# CY8C4xxx register map
File version: 0.1
Registers are 8-bit, read-write, no defined reset value unless marked. A register's access mark holds for its fields unless they carry their own. Offsets are from the block's base; [hi:lo] are bit positions; {n}, {i} and the like mark numbered series; 'fields as' and 'values as' point back to an identical list.

## SCB0 (part 2 of 2) — Serial Communications Block (SPI/UART/I2C)
Base 0x40060000
Same registers: SCB1 0x40070000
0x104 BIST_DATA 32-bit
  [15:0] RAM_DATA — Data pattern for BIST sequence. If RAM_WORD=0, only bits [7:0] are used.
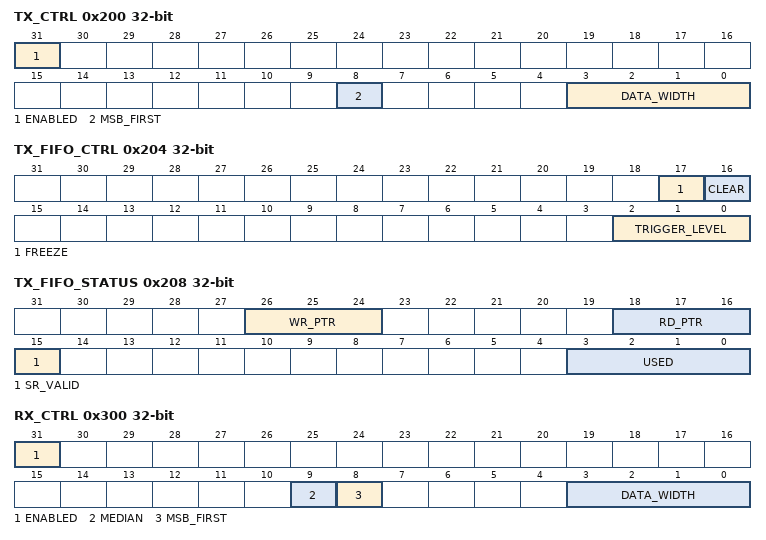
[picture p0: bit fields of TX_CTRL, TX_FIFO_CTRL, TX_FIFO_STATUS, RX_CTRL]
0x200 TX_CTRL 32-bit — Transmitter control register.
  [31] ENABLED — Transmitter enabled. The transmitter should be enabled for all protocols that transmit data (from either the EZ memory or from the TX FIFO). If not enabled, the protocol may not function as it does not get data to transmit.
  [8] MSB_FIRST — Least significant bit first ('0') or most significant bit first ('1'). For I2C, this field should be '1'.
  [3:0] DATA_WIDTH — Dataframe width. DATA_WIDTH + 1 is the amount of bits in a transmitted data frame. This number does not include start, parity and stop bits. For UART mode, the valid range is [3, 8]. For SPI, the valid range is [3, 15]. For I2C the only valid value is 7.
0x204 TX_FIFO_CTRL 32-bit — Transmitter FIFO control register.
  [17] FREEZE — When '1', hardware reads from the transmitter FIFO do not remove FIFO entries. Freeze will not advance the TX FIFO read pointer.
  [16] CLEAR — When '1', the transmitter FIFO and transmitter shift register are cleared/invalidated. Invalidation will last for as long as this field is '1'. If a quick clear/invalidation is required, the field should be set to '1' and be followed by a set to '0'. If a clear/invalidation is required for an extended time period, the field should be set to '1' during the complete time period.
  [2:0] TRIGGER_LEVEL — Trigger level. When the transmitter FIFO has less entries than the amount of this field, a transmitter trigger event is generated.
0x208 TX_FIFO_STATUS 32-bit — Transmitter FIFO status register.
  [26:24] WR_PTR ro — FIFO write pointer: FIFO location at which a new data frame is written.
  [18:16] RD_PTR ro — FIFO read pointer: FIFO location from which a data frame is read by the hardware.
  [15] SR_VALID ro — Indicates whether the TX shift registers holds a valid data frame ('1') or not ('0'). The shift register can be considered the top of the TX FIFO (the data frame is not included in the USED field of the TX FIFO). The shift register is a working register and holds the data frame that is currently transmitted (when the protocol state machine is transmitting a data frame) or the data frame that is tranmitted next (when the protocol state machine is not transmitting a data frame).
  [3:0] USED ro — Amount of enties in the transmitter FIFO. The value of this field ranges from 0 to 8.
0x240 TX_FIFO_WR 32-bit — Transmitter FIFO write register.
  [15:0] DATA wo — Data frame written into the transmitter FIFO. Behavior is similar to that of a PUSH operation.
0x300 RX_CTRL 32-bit — Receiver control register.
  [31] ENABLED — Receiver enabled. The receiver should be enabled for all protocols that receive data (to either the EZ memory or to the RX FIFO). If not enabled, the protocol may not function or received data may get lost.
  [9] MEDIAN — Median filter. When '1', a digital 3 taps median filter is performed on input interface lines. This filter should reduce the susceptability to errors. However, its requires higher oversampling values. For UART IrDA submode, this field should always be '1'.
  [8] MSB_FIRST — Least significant bit first ('0') or most significant bit first ('1'). For I2C, this field should be '1'.
  [3:0] DATA_WIDTH — Dataframe width. DATA_WIDTH + 1 is the expected amount of bits in received data frame. This number does not include start, parity and stop bits. For UART mode, the valid range is [3, 8]. For SPI, the valid range is [3, 15]. For I2C the only valid value is 7. In EZ mode (for both SPI and I2C), the only valid value is 7.
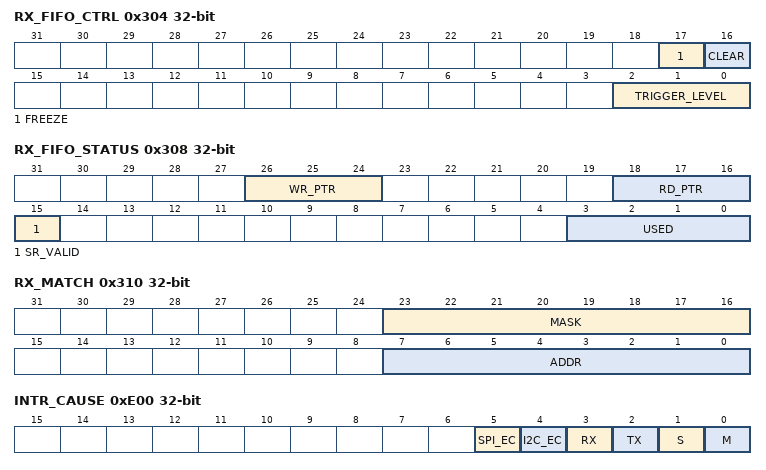
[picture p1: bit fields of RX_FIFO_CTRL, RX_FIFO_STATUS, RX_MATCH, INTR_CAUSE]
0x304 RX_FIFO_CTRL 32-bit — Receiver FIFO control register.
  [17] FREEZE — When '1', hardware writes to the receiver FIFO have no effect. Freeze will not advance the RX FIFO write pointer.
  [16] CLEAR — When '1', the receiver FIFO and receiver shift register are cleared/invalidated. Invalidation will last for as long as this field is '1'. If a quick clear/invalidation is required, the field should be set to '1' and be followed by a set to '0'. If a clear/invalidation is required for an extended time period, the field should be set to '1' during the complete time period.
  [2:0] TRIGGER_LEVEL — Trigger level. When the receiver FIFO has more entries than the amount of this field, a receiver trigger event is generated.
0x308 RX_FIFO_STATUS 32-bit — Receiver FIFO status register.
  [26:24] WR_PTR ro — FIFO write pointer: FIFO location at which a new data frame is written by the hardware.
  [18:16] RD_PTR ro — FIFO read pointer: FIFO location from which a data frame is read.
  [15] SR_VALID ro — Indicates whether the RX shift registers holds a (partial) valid data frame ('1') or not ('0'). The shift register can be considered the bottom of the RX FIFO (the data frame is not included in the USED field of the RX FIFO). The shift register is a working register and holds the data frame that is currently being received (when the protocol state machine is receiving a data frame).
  [3:0] USED ro — Amount of enties in the receiver FIFO. The value of this field ranges from 0 to 8.
0x310 RX_MATCH 32-bit — Slave address and mask register.
  [23:16] MASK — Slave device address mask. This field is a 8 bit mask that specifies which of the ADDR field bits in the SCB_RX_MATCH_ADDR register take part in the matching of the slave address: MATCH = ((ADDR & MASK) == ("slave address" & MASK)).
  [7:0] ADDR — Slave device address. For UART multi-processor moden all eight bits a reused. For I2C, bit 0 of the register is not used. This reflects the organization of the first transmitted byte in a I2C transfer: the first 7 bits represent the address of the addressed slave, and the next 1 bit is a read/write indicator ('0': write, '1': read).
0x340 RX_FIFO_RD 32-bit — Receiver FIFO read register.
  [15:0] DATA ro — Data read from the receiver FIFO. Reading a data frame will remove the data frame from the FIFO; i.e. behavior is similar to that of a POP operation. This register has a side effect when read by software: a data frame is removed from the FIFO. This may be undesirable during debug; i.e. a read during debug should NOT have a side effect. To this end, the IP uses the AHB-Lite "hmaster[0]" input signal. When this signal is '1' in the address cycle of a bus transfer, a read transfer will not have a side effect. As a result, a read from this register will not remove a data frame from the FIFO. As a result, a read from this register behaves as a read from the SCB_RX_FIFO_RD_SILENT register.
0x344 RX_FIFO_RD_SILENT 32-bit — Receiver FIFO read register.
  [15:0] DATA ro — Data read from the receiver FIFO. Reading a data frame will NOT remove the data frame from the FIFO; i.e. behavior is similar to that of a PEEK operation.
{0x400+4i} EZ_DATA{i:02} 32-bit (i=0..31) — EZ memory location registers.
  [7:0] EZ_DATA — Data in EZ memory location.
0xE00 INTR_CAUSE 32-bit — Active clocked interrupt signal register
  [5] SPI_EC ro — Externally clocked SPI interrupt active ("interrupt_spi_ec"): INTR_SPI_EC_MASKED != 0.
  [4] I2C_EC ro — Externally clock I2C interrupt active ("interrupt_i2c_ec"): INTR_I2C_EC_MASKED != 0.
  [3] RX ro — Receiver interrupt active ("interrupt_rx"): INTR_RX_MASKED != 0.
  [2] TX ro — Transmitter interrupt active ("interrupt_tx"): INTR_TX_MASKED != 0.
  [1] S ro — Slave interrupt active ("interrupt_slave"): INTR_S_MASKED != 0.
  [0] M ro — Master interrupt active ("interrupt_master"): INTR_M_MASKED != 0.
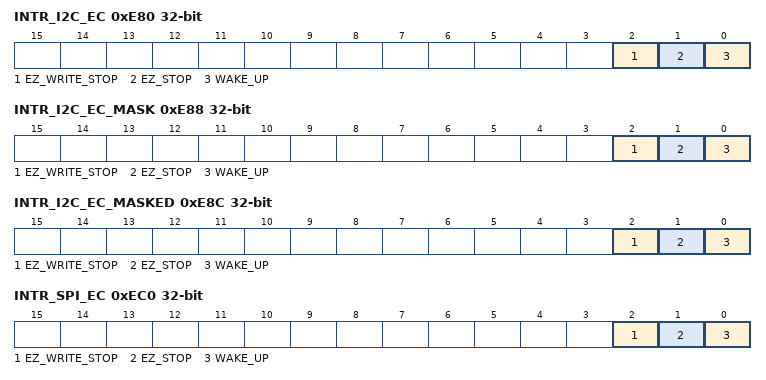
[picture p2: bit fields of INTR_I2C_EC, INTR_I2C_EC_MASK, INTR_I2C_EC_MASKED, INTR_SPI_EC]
0xE80 INTR_I2C_EC 32-bit — Externally clocked I2C interrupt request register
  [2] EZ_WRITE_STOP write-once — STOP detection after a write transfer occurred (only available in EZ mode). Active on detected STOP when externally clocked operation is on. Only generated when a write transfer to the EZ memory occurred between the STOP and the preceding START (note that multiple REPEATED STARTs may have happened in between the START and STOP). If a write transfer only modified the EZ address, and not the EZ memory, this event is NOT generated.
  [1] EZ_STOP write-once — STOP detection (only available in EZ mode). Active on detected STOP when externally clocked operation is on.
  [0] WAKE_UP write-once — Wake up request. Active on incoming slave request (with address match) when externally clocked selection is '1'.
0xE88 INTR_I2C_EC_MASK 32-bit — Externally clocked I2C interrupt mask register
  [2] EZ_WRITE_STOP — Mask bit for corresponding bit in interrupt request register.
  [1] EZ_STOP — Mask bit for corresponding bit in interrupt request register.
  [0] WAKE_UP — Mask bit for corresponding bit in interrupt request register.
0xE8C INTR_I2C_EC_MASKED 32-bit — Externally clocked I2C interrupt masked register
  [2] EZ_WRITE_STOP ro — Logical and of corresponding request and mask bits.
  [1] EZ_STOP ro — Logical and of corresponding request and mask bits.
  [0] WAKE_UP ro — Logical and of corresponding request and mask bits.
0xEC0 INTR_SPI_EC 32-bit — Externally clocked SPI interrupt request register
  [2] EZ_WRITE_STOP write-once — STOP detection after a write transfer occurred. Active on detected STOP (deselection) when externally clocked operation is on (only available in EZ mode). If a write transfer only transferred the EZ address, this event will not be generated. This event is an indication that a EZ memory location may have changed contents.
  [1] EZ_STOP write-once — STOP detection. Active on detected STOP (deselection) when externally clocked operation is on (only available in EZ mode).
  [0] WAKE_UP write-once — Wake up request. Active on incoming slave request when externally clocked selection is '1'.
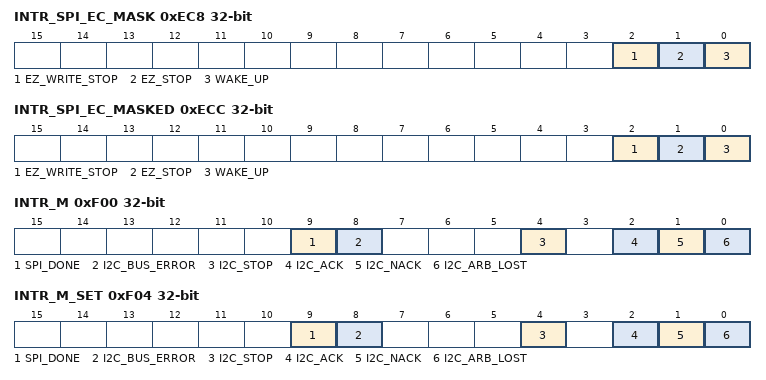
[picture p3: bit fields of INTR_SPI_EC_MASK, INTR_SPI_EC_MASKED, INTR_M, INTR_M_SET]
0xEC8 INTR_SPI_EC_MASK 32-bit — Externally clocked SPI interrupt mask register
  fields as INTR_I2C_EC_MASK
0xECC INTR_SPI_EC_MASKED 32-bit — Externally clocked SPI interrupt masked register
  fields as INTR_I2C_EC_MASKED
0xF00 INTR_M 32-bit — Master interrupt request register.
  [9] SPI_DONE write-once — SPI master transfer done event: all data frames in the transmit FIFO are sent and the transmit FIFO is empty. Set to '1', when event is detected. Write with '1' to clear bit.
  [8] I2C_BUS_ERROR write-once — I2C master bus error (unexpected detection of START or STOP condition). Set to '1', when event is detected. Write with '1' to clear bit.
  [4] I2C_STOP write-once — I2C master STOP. Set to '1', when the master has transmitted a STOP. Write with '1' to clear bit.
  [2] I2C_ACK write-once — I2C master acknowledgement. Set to '1', when the master receives a ACK (typically after the master transmitted the slave address or TX data). Write with '1' to clear bit.
  [1] I2C_NACK write-once — I2C master negative acknowledgement. Set to '1', when the master receives a NACK (typically after the master transmitted the slave address or TX data). Write with '1' to clear bit.
  [0] I2C_ARB_LOST write-once — I2C master lost arbitration: the value driven by the master on the SDA line is not the same as the value observed on the SDA line. Set to '1', when event is detected. Write with '1' to clear bit.
0xF04 INTR_M_SET 32-bit — Master interrupt set request register
  [9] SPI_DONE write-once — Write with '1' to set corresponding bit in interrupt request register.
  [8] I2C_BUS_ERROR write-once — Write with '1' to set corresponding bit in interrupt request register.
  [4] I2C_STOP write-once — Write with '1' to set corresponding bit in interrupt request register.
  [2] I2C_ACK write-once — Write with '1' to set corresponding bit in interrupt request register.
  [1] I2C_NACK write-once — Write with '1' to set corresponding bit in interrupt request register.
  [0] I2C_ARB_LOST write-once — Write with '1' to set corresponding bit in interrupt request register.
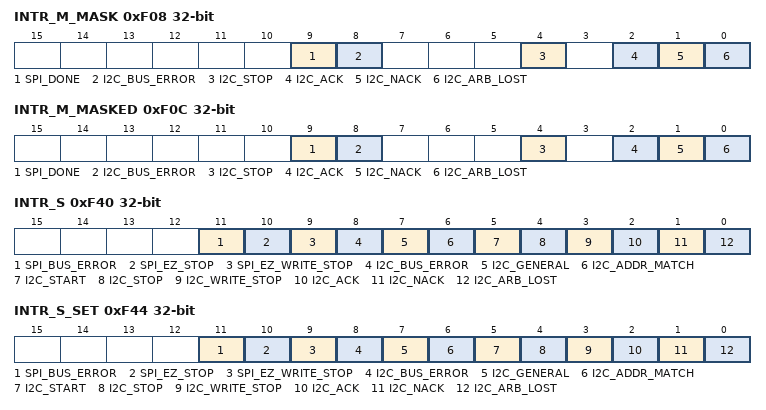
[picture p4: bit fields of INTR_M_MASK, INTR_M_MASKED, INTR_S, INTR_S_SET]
0xF08 INTR_M_MASK 32-bit — Master interrupt mask register.
  [9] SPI_DONE — Mask bit for corresponding bit in interrupt request register.
  [8] I2C_BUS_ERROR — Mask bit for corresponding bit in interrupt request register.
  [4] I2C_STOP — Mask bit for corresponding bit in interrupt request register.
  [2] I2C_ACK — Mask bit for corresponding bit in interrupt request register.
  [1] I2C_NACK — Mask bit for corresponding bit in interrupt request register.
  [0] I2C_ARB_LOST — Mask bit for corresponding bit in interrupt request register.
0xF0C INTR_M_MASKED 32-bit — Master interrupt masked request register
  [9] SPI_DONE ro — Logical and of corresponding request and mask bits.
  [8] I2C_BUS_ERROR ro — Logical and of corresponding request and mask bits.
  [4] I2C_STOP ro — Logical and of corresponding request and mask bits.
  [2] I2C_ACK ro — Logical and of corresponding request and mask bits.
  [1] I2C_NACK ro — Logical and of corresponding request and mask bits.
  [0] I2C_ARB_LOST ro — Logical and of corresponding request and mask bits.
0xF40 INTR_S 32-bit — Slave interrupt request register.
  [11] SPI_BUS_ERROR write-once — SPI slave deselected at an unexpected time in the SPI transfer. Set to '1', when event is detected. Write with '1' to clear bit. The Firmware may decide to clear the TX and RX FIFOs in case of this error.
  [10] SPI_EZ_STOP write-once — SPI slave deselected after any EZ SPI transfer occured. Set to '1', when event is detected. Write with '1' to clear bit.
  [9] SPI_EZ_WRITE_STOP write-once — SPI slave deselected after a write EZ SPI transfer occurred. Set to '1', when event is detected. Write with '1' to clear bit.
  [8] I2C_BUS_ERROR write-once — I2C slave bus error (unexpected detection of START or STOP condition). This should not occur, it represents erroneous I2C bus behaviour. In case of a bus error, the I2C slave state machine abort the ongoing transfer. Set to '1', when event is detected. Write with '1' to clear bit. The Firmware may decide to clear the TX and RX FIFOs in case of this error.
  [7] I2C_GENERAL write-once — I2C slave general call address received. If CTRL.ADDR_ACCEPT, the received address 0x00 (including the R/W bit) is available in the RX FIFO. In the case of externally clocked address matching (CTRL.EC_AM_MODE is '1') and internally clocked operation (CTRL.EC_OP_MODE is '0'), this field is set when the event is detected. Set to '1', when event is detected. Write with '1' to clear bit.
  [6] I2C_ADDR_MATCH write-once — I2C slave matching address received. If CTRL.ADDR_ACCEPT, the received address (including the R/W bit) is available in the RX FIFO. In the case of externally clocked address matching (CTRL.EC_AM_MODE is '1') and internally clocked operation (CTRL.EC_OP_MODE is '0'), this field is set when the event is detected. Set to '1', when event is detected. Write with '1' to clear bit.
  [5] I2C_START write-once — I2C slave START received. Set to '1', when START or REPEATED START event is detected. In the case of externally clocked address matching (CTRL.EC_AM_MODE is '1') and internally clocked operation (CTRL.EC_OP_MODE is '0'), this field is NOT set. Instead the Firmware can rely on I2C_ADDR_MATCH and I2C_GENERAL. Write with '1' to clear bit.
  [4] I2C_STOP write-once — I2C STOP event for I2C (read or write) transfer intended for this slave (address matching is performed). Set to '1', when STOP or REPEATED START event is detected. The REPEATED START event is included in this interrupt cause such that the I2C transfers seperated by a REPEATED START can be distinguished and potentially treated seperately by the Firmware. Note that the second I2C transfer may be to a different slave address. Write with '1' to clear bit.
  [3] I2C_WRITE_STOP write-once — I2C STOP event for I2C write transfer intended for this slave (address matching is performed). In non EZ mode, the event is detected on any I2C write transfer intended for this slave. In EZ mode, the event is detected only on I2C write transfers that have EZ data written to the memory structure (an I2C write transfer that only communicates an EZ address, will not result in this event being detected). Set to '1', when STOP or REPEATED START event is detected. The REPEATED START event is included in this interrupt cause such that the I2C transfers seperated by a REPEATED START can be distinguished and potentially treated seperately by the Firmware. Note that the second I2C transfer may be to a different slave address. Write with '1' to clear bit.
  [2] I2C_ACK write-once — I2C slave acknowledgement received. Set to '1', when the slave receives a ACK (typically after the slave transmitted TX data). Write with '1' to clear bit.
  [1] I2C_NACK write-once — I2C slave negative acknowledgement received. Set to '1', when the slave receives a NACK (typically after the slave transmitted TX data). Write with '1' to clear bit.
  [0] I2C_ARB_LOST write-once — I2C slave lost arbitration: the value driven on the SDA line is not the same as the value observed on the SDA line (while the SCL line is '1'). This should not occur, it represents erroneous I2C bus behaviour. In case of lost arbitration, the I2C slave state machine abort the ongoing transfer. Set to '1', when event is detected. Write with '1' to clear bit. The Firmware may decide to clear the TX and RX FIFOs in case of this error.
0xF44 INTR_S_SET 32-bit — Slave interrupt set request register.
  [11] SPI_BUS_ERROR write-once — Write with '1' to set corresponding bit in interrupt request register.
  [10] SPI_EZ_STOP write-once — Write with '1' to set corresponding bit in interrupt request register.
  [9] SPI_EZ_WRITE_STOP write-once — Write with '1' to set corresponding bit in interrupt request register.
  [8] I2C_BUS_ERROR write-once — Write with '1' to set corresponding bit in interrupt request register.
  [7] I2C_GENERAL write-once — Write with '1' to set corresponding bit in interrupt request register.
  [6] I2C_ADDR_MATCH write-once — Write with '1' to set corresponding bit in interrupt request register.
  [5] I2C_START write-once — Write with '1' to set corresponding bit in interrupt request register.
  [4] I2C_STOP write-once — Write with '1' to set corresponding bit in interrupt request register.
  [3] I2C_WRITE_STOP write-once — Write with '1' to set corresponding bit in interrupt request register.
  [2] I2C_ACK write-once — Write with '1' to set corresponding bit in interrupt request register.
  [1] I2C_NACK write-once — Write with '1' to set corresponding bit in interrupt request register.
  [0] I2C_ARB_LOST write-once — Write with '1' to set corresponding bit in interrupt request register.
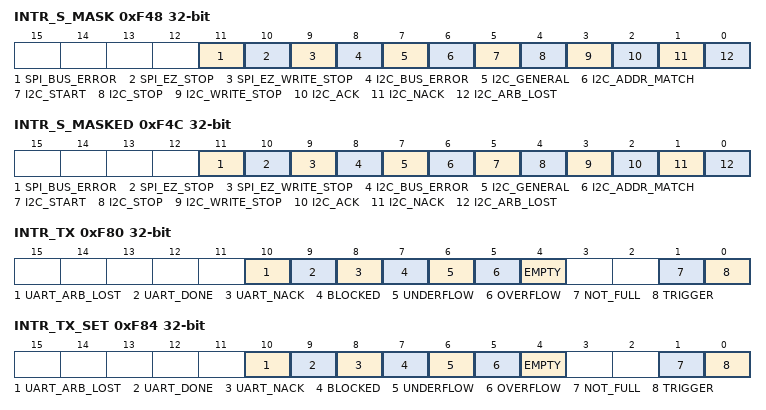
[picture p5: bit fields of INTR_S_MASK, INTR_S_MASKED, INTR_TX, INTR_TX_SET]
0xF48 INTR_S_MASK 32-bit — Slave interrupt mask register.
  [11] SPI_BUS_ERROR — Mask bit for corresponding bit in interrupt request register.
  [10] SPI_EZ_STOP — Mask bit for corresponding bit in interrupt request register.
  [9] SPI_EZ_WRITE_STOP — Mask bit for corresponding bit in interrupt request register.
  [8] I2C_BUS_ERROR — Mask bit for corresponding bit in interrupt request register.
  [7] I2C_GENERAL — Mask bit for corresponding bit in interrupt request register.
  [6] I2C_ADDR_MATCH — Mask bit for corresponding bit in interrupt request register.
  [5] I2C_START — Mask bit for corresponding bit in interrupt request register.
  [4] I2C_STOP — Mask bit for corresponding bit in interrupt request register.
  [3] I2C_WRITE_STOP — Mask bit for corresponding bit in interrupt request register.
  [2] I2C_ACK — Mask bit for corresponding bit in interrupt request register.
  [1] I2C_NACK — Mask bit for corresponding bit in interrupt request register.
  [0] I2C_ARB_LOST — Mask bit for corresponding bit in interrupt request register.
0xF4C INTR_S_MASKED 32-bit — Slave interrupt masked request register
  [11] SPI_BUS_ERROR ro — Logical and of corresponding request and mask bits.
  [10] SPI_EZ_STOP ro — Logical and of corresponding request and mask bits.
  [9] SPI_EZ_WRITE_STOP ro — Logical and of corresponding request and mask bits.
  [8] I2C_BUS_ERROR ro — Logical and of corresponding request and mask bits.
  [7] I2C_GENERAL ro — Logical and of corresponding request and mask bits.
  [6] I2C_ADDR_MATCH ro — Logical and of corresponding request and mask bits.
  [5] I2C_START ro — Logical and of corresponding request and mask bits.
  [4] I2C_STOP ro — Logical and of corresponding request and mask bits.
  [3] I2C_WRITE_STOP ro — Logical and of corresponding request and mask bits.
  [2] I2C_ACK ro — Logical and of corresponding request and mask bits.
  [1] I2C_NACK ro — Logical and of corresponding request and mask bits.
  [0] I2C_ARB_LOST ro — Logical and of corresponding request and mask bits.
0xF80 INTR_TX 32-bit — Transmitter interrupt request register.
  [10] UART_ARB_LOST write-once — UART lost arbitration: the value driven on the TX line is not the same as the value observed on the RX line. This condition event is usefull when transmitter and receiver share a TX/RX line. This is the case in LIN or SmartCard modes. Set to '1', when event is detected. Write with '1' to clear bit.
  [9] UART_DONE write-once — UART transmitter done event. This happens when the IP is done transferring all data in the TX FIFO; i.e. EMPTY is '1'. Set to '1', when event is detected. Write with '1' to clear bit.
  [8] UART_NACK write-once — UART transmitter received a negative acknowledgement in SmartCard mode. Set to '1', when event is detected. Write with '1' to clear bit.
  [7] BLOCKED write-once — AHB-Lite write transfer can not get access to the EZ memory (EZ data access), due to an externally clocked EZ access. This may happen when STATUS.EC_BUSY is '1'.
  [6] UNDERFLOW write-once — Attempt to read from an empty TX FIFO. This happens when the IP is ready to transfer data and EMPTY is '1'. Set to '1', when event is detected. Write with '1' to clear bit.
  [5] OVERFLOW write-once — Attempt to write to a full TX FIFO. Set to '1', when event is detected. Write with '1' to clear bit.
  [4] EMPTY write-once — TX FIFO is empty; i.e. it has 0 entries. Set to '1', when event is detected. Write with '1' to clear bit.
  [1] NOT_FULL write-once — TX FIFO is not full. Set to '1', when event is detected. Write with '1' to clear bit.
  [0] TRIGGER write-once — Less entries in the TX FIFO than the value specified by TRIGGER_LEVEL in SCB_TX_FIFO_CTL. Set to '1', when event is detected. Write with '1' to clear bit.
0xF84 INTR_TX_SET 32-bit — Transmitter interrupt set request register
  [10] UART_ARB_LOST write-once — Write with '1' to set corresponding bit in interrupt request register.
  [9] UART_DONE write-once — Write with '1' to set corresponding bit in interrupt request register.
  [8] UART_NACK write-once — Write with '1' to set corresponding bit in interrupt request register.
  [7] BLOCKED write-once — Write with '1' to set corresponding bit in interrupt request register.
  [6] UNDERFLOW write-once — Write with '1' to set corresponding bit in interrupt request register.
  [5] OVERFLOW write-once — Write with '1' to set corresponding bit in interrupt request register.
  [4] EMPTY write-once — Write with '1' to set corresponding bit in interrupt request register.
  [1] NOT_FULL write-once — Write with '1' to set corresponding bit in interrupt request register.
  [0] TRIGGER write-once — Write with '1' to set corresponding bit in interrupt request register.
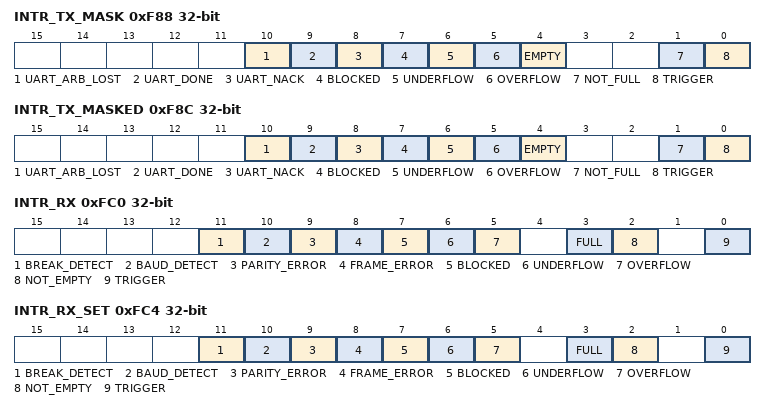
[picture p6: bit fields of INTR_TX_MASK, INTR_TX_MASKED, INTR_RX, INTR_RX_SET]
0xF88 INTR_TX_MASK 32-bit — Transmitter interrupt mask register.
  [10] UART_ARB_LOST — Mask bit for corresponding bit in interrupt request register.
  [9] UART_DONE — Mask bit for corresponding bit in interrupt request register.
  [8] UART_NACK — Mask bit for corresponding bit in interrupt request register.
  [7] BLOCKED — Mask bit for corresponding bit in interrupt request register.
  [6] UNDERFLOW — Mask bit for corresponding bit in interrupt request register.
  [5] OVERFLOW — Mask bit for corresponding bit in interrupt request register.
  [4] EMPTY — Mask bit for corresponding bit in interrupt request register.
  [1] NOT_FULL — Mask bit for corresponding bit in interrupt request register.
  [0] TRIGGER — Mask bit for corresponding bit in interrupt request register.
0xF8C INTR_TX_MASKED 32-bit — Transmitter interrupt masked request register
  [10] UART_ARB_LOST ro — Logical and of corresponding request and mask bits.
  [9] UART_DONE ro — Logical and of corresponding request and mask bits.
  [8] UART_NACK ro — Logical and of corresponding request and mask bits.
  [7] BLOCKED ro — Logical and of corresponding request and mask bits.
  [6] UNDERFLOW ro — Logical and of corresponding request and mask bits.
  [5] OVERFLOW ro — Logical and of corresponding request and mask bits.
  [4] EMPTY ro — Logical and of corresponding request and mask bits.
  [1] NOT_FULL ro — Logical and of corresponding request and mask bits.
  [0] TRIGGER ro — Logical and of corresponding request and mask bits.
0xFC0 INTR_RX 32-bit — Receiver interrupt request register.
  [11] BREAK_DETECT write-once — Break detection is successful: the line is '0' for UART_RX_CTRL.BREAK_WIDTH + 1 bit period. Can occur at any time to address unanticipated break fields; i.e. "break-in-data" is supported. This feature is supported for the UART standard and LIN submodes. For the UART standard submodes, ongoing receipt of data frames is NOT affected; i.e. Firmware is ecpected to take the proper action. For the LIN submode, possible ongoing receipt of a data frame is stopped and the (partially) received data frame is dropped and baud rate detection is started. Set to '1', when event is detected. Write with '1' to clear bit.
  [10] BAUD_DETECT write-once — LIN baudrate detection is completed. The receiver software uses the UART_RX_STATUS.BR_COUNTER value to set the right IP clock (from the programmable clock IP) to guarantee successful receipt of the first LIN data frame (Protected Identifier Field) after the synchronization byte. Set to '1', when event is detected. Write with '1' to clear bit.
  [9] PARITY_ERROR write-once — Parity error in received data frame. Set to '1', when event is detected. Write with '1' to clear bit. If UART_RX_CTL.DROP_ON_PARITY_ERROR is '1', the received frame is dropped. If UART_RX_CTL.DROP_ON_PARITY_ERROR is '0', the received frame is send to the RX FIFO. In SmartCard submode, negatively acknowledged data frames generate a parity error. Note that Firmware can only identify the erroneous data frame in the RX FIFO if it is fast enough to read the data frame before the hardware writes a next data frame into the RX FIFO.
  [8] FRAME_ERROR write-once — Frame error in received data frame. Set to '1', when event is detected. Write with '1' to clear bit. This can be either a start or stop bit(s) error:?Start bit error: after the detection of the beginning of a start bit period (RX line changes from '1' to '0'), the middle of the start bit period is sampled erroneously (RX line is '1'). Note: a start bit error is detected BEFORE a data frame is received.?Stop bit error: the RX line is sampled as '0', but a '1' was expected. Note: a stop bit error may result in failure to receive successive data frame(s). Note: a stop bit error is detected AFTER a data frame is received.??A stop bit error is detected after a data frame is received, and the UART_RX_CTL.DROP_ON_FRAME_ERROR field specifies whether the received frame is dropped or send to the RX FIFO. If UART_RX_CTL.DROP_ON_FRAME_ERROR is '1', the received data frame is dropped. If UART_RX_CTL.DROP_ON_FRAME_ERROR is '0', the received data frame is send to the RX FIFO. Note that Firmware can only identify the erroneous data frame in the RX FIFO if it is fast enough to read the data frame before the hardware writes a next data frame into the RX FIFO; i.e. the RX FIFO does not have error flags to tag erroneous data frames.
  [7] BLOCKED write-once — AHB-Lite read transfer can not get access to the EZ memory (EZ_DATA accesses), due to an externally clocked EZ access. This may happen when STATUS.EC_BUSY is '1'.
  [6] UNDERFLOW write-once — Attempt to read from an empty RX FIFO. Set to '1', when event is detected. Write with '1' to clear bit.
  [5] OVERFLOW write-once — Attempt to write to a full RX FIFO. Set to '1', when event is detected. Write with '1' to clear bit. Note: in I2C mode, the OVERFLOW is set when a data frame is received and the RX FIFO is full, independent of whether it is ACK'd or NACK'd.
  [3] FULL write-once — RX FIFO is full. Set to '1', when event is detected. Write with '1' to clear bit. Note that received data frames are lost when the RX FIFO is full
  [2] NOT_EMPTY write-once — RX FIFO is not empty. Set to '1', when event is detected. Write with '1' to clear bit.
  [0] TRIGGER write-once — More entries in the RX FIFO than the value specified by TRIGGER_LEVEL in SCB_RX_FIFO_CTL. Set to '1', when event is detected. Write with '1' to clear bit.
0xFC4 INTR_RX_SET 32-bit — Receiver interrupt set request register.
  [11] BREAK_DETECT write-once — Write with '1' to set corresponding bit in interrupt status register.
  [10] BAUD_DETECT write-once — Write with '1' to set corresponding bit in interrupt status register.
  [9] PARITY_ERROR write-once — Write with '1' to set corresponding bit in interrupt status register.
  [8] FRAME_ERROR write-once — Write with '1' to set corresponding bit in interrupt status register.
  [7] BLOCKED write-once — Write with '1' to set corresponding bit in interrupt status register.
  [6] UNDERFLOW write-once — Write with '1' to set corresponding bit in interrupt status register.
  [5] OVERFLOW write-once — Write with '1' to set corresponding bit in interrupt status register.
  [3] FULL write-once — Write with '1' to set corresponding bit in interrupt status register.
  [2] NOT_EMPTY write-once — Write with '1' to set corresponding bit in interrupt status register.
  [0] TRIGGER write-once — Write with '1' to set corresponding bit in interrupt request register.
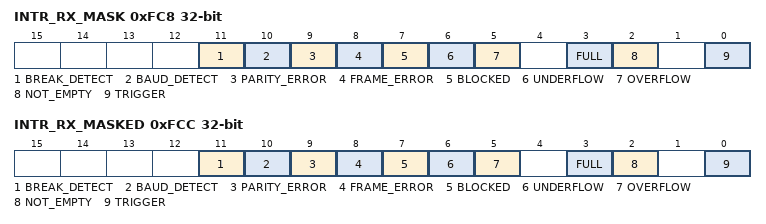
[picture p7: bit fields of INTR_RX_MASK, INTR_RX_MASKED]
0xFC8 INTR_RX_MASK 32-bit — Receiver interrupt mask register.
  [11] BREAK_DETECT — Mask bit for corresponding bit in interrupt request register.
  [10] BAUD_DETECT — Mask bit for corresponding bit in interrupt request register.
  [9] PARITY_ERROR — Mask bit for corresponding bit in interrupt request register.
  [8] FRAME_ERROR — Mask bit for corresponding bit in interrupt request register.
  [7] BLOCKED — Mask bit for corresponding bit in interrupt request register.
  [6] UNDERFLOW — Mask bit for corresponding bit in interrupt request register.
  [5] OVERFLOW — Mask bit for corresponding bit in interrupt request register.
  [3] FULL — Mask bit for corresponding bit in interrupt request register.
  [2] NOT_EMPTY — Mask bit for corresponding bit in interrupt request register.
  [0] TRIGGER — Mask bit for corresponding bit in interrupt request register.
0xFCC INTR_RX_MASKED 32-bit — Receiver interrupt masked request register
  [11] BREAK_DETECT ro — Logical and of corresponding request and mask bits.
  [10] BAUD_DETECT ro — Logical and of corresponding request and mask bits.
  [9] PARITY_ERROR ro — Logical and of corresponding request and mask bits.
  [8] FRAME_ERROR ro — Logical and of corresponding request and mask bits.
  [7] BLOCKED ro — Logical and of corresponding request and mask bits.
  [6] UNDERFLOW ro — Logical and of corresponding request and mask bits.
  [5] OVERFLOW ro — Logical and of corresponding request and mask bits.
  [3] FULL ro — Logical and of corresponding request and mask bits.
  [2] NOT_EMPTY ro — Logical and of corresponding request and mask bits.
  [0] TRIGGER ro — Logical and of corresponding request and mask bits.
